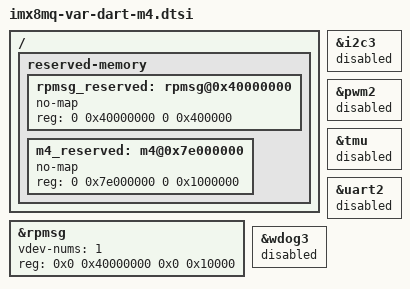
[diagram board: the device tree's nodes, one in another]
// SPDX-License-Identifier: (GPL-2.0 OR MIT)
/*
 * Copyright 2017 NXP
 * Copyright 2019-2020 Variscite Ltd.
 */

/ {
	reserved-memory {
		#address-cells = <2>;
		#size-cells = <2>;
		ranges;

		rpmsg_reserved: rpmsg@0x40000000 {
			no-map;
			reg = <0 0x40000000 0 0x400000>;
		};

		m4_reserved: m4@0x7e000000 {
			no-map;
			reg = <0 0x7e000000 0 0x1000000>;
		};

	};
};

&i2c3 {
	status = "disabled";
};

&pwm2 {
	status = "disabled";
};

&rpmsg{
	/*
	 * 64K for one rpmsg instance:
	 * --0x40000000~0x4000ffff: pingpong
	 */
	vdev-nums = <1>;
	reg = <0x0 0x40000000 0x0 0x10000>;
	status = "okay";
};

&tmu {
	status = "disabled";
};

&uart2 {
	status = "disabled";
};

&wdog3{
	status = "disabled";
};
